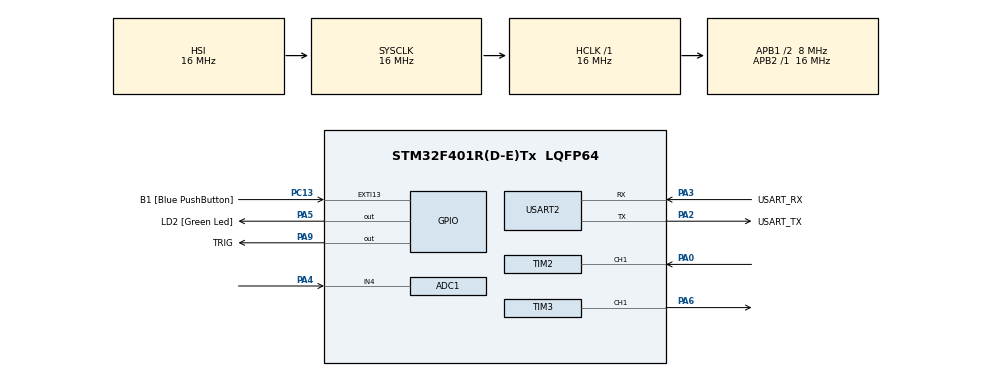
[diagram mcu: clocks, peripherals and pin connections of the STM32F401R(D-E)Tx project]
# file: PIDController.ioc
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ADC1.Channel-0\#ChannelRegularConversion=ADC_CHANNEL_4
ADC1.NbrOfConversionFlag=1
ADC1.Rank-0\#ChannelRegularConversion=1
ADC1.SamplingTime-0\#ChannelRegularConversion=ADC_SAMPLETIME_480CYCLES
ADC1.master=1
FREERTOS.Tasks01=defaultTask,24,128,StartDefaultTask,Default,NULL,Dynamic,NULL,NULL
FREERTOS.configTOTAL_HEAP_SIZE=24576
FREERTOS.configUSE_NEWLIB_REENTRANT=1
Mcu.Family=STM32F4
Mcu.Name=STM32F401R(D-E)Tx
Mcu.Package=LQFP64
NVIC.PriorityGroup=NVIC_PRIORITYGROUP_4
NVIC.TIM2_IRQn=true\:5\:0\:false\:false\:true\:true\:true\:true\:true
NVIC.TIM4_IRQn=true\:5\:0\:false\:false\:true\:true\:true\:true\:true
NVIC.TIM5_IRQn=true\:15\:0\:false\:false\:true\:false\:false\:true\:true
NVIC.TimeBase=TIM5_IRQn
NVIC.TimeBaseIP=TIM5
PA0-WKUP.Signal=S_TIM2_CH1_ETR
PA13.GPIO_Label=TMS
PA13.Mode=Serial_Wire
PA13.Signal=SYS_JTMS-SWDIO
PA14.GPIO_Label=TCK
PA14.Mode=Serial_Wire
PA14.Signal=SYS_JTCK-SWCLK
PA2.GPIO_Label=USART_TX
PA2.GPIO_Mode=GPIO_MODE_AF_PP
PA2.GPIO_PuPd=GPIO_NOPULL
PA2.GPIO_Speed=GPIO_SPEED_FREQ_LOW
PA2.Mode=Asynchronous
PA2.Signal=USART2_TX
PA3.GPIO_Label=USART_RX
PA3.GPIO_Mode=GPIO_MODE_AF_PP
PA3.GPIO_PuPd=GPIO_NOPULL
PA3.GPIO_Speed=GPIO_SPEED_FREQ_LOW
PA3.Mode=Asynchronous
PA3.Signal=USART2_RX
PA4.Signal=ADCx_IN4
PA5.GPIO_Label=LD2 [Green Led]
PA5.GPIO_Mode=GPIO_MODE_OUTPUT_PP
PA5.GPIO_PuPd=GPIO_NOPULL
PA5.GPIO_Speed=GPIO_SPEED_FREQ_LOW
PA5.Signal=GPIO_Output
PA6.Signal=S_TIM3_CH1
PA9.GPIO_Label=TRIG
PA9.Signal=GPIO_Output
PB3.GPIO_Label=SWO
PB3.Signal=SYS_JTDO-SWO
PC13-ANTI_TAMP.GPIO_Label=B1 [Blue PushButton]
PC13-ANTI_TAMP.GPIO_ModeDefaultEXTI=GPIO_MODE_IT_FALLING
PC13-ANTI_TAMP.GPIO_PuPd=GPIO_NOPULL
PC13-ANTI_TAMP.Signal=GPXTI13
PC14-OSC32_IN.Signal=RCC_OSC32_IN
PC15-OSC32_OUT.Signal=RCC_OSC32_OUT
PH0\ -\ OSC_IN.Signal=RCC_OSC_IN
PH1\ -\ OSC_OUT.Signal=RCC_OSC_OUT
ProjectManager.HeapSize=0x200
ProjectManager.StackSize=0x400
ProjectManager.TargetToolchain=STM32CubeIDE
RCC.48MHZClocksFreq_Value=18285714.285714287
RCC.AHBCLKDivider=RCC_SYSCLK_DIV1
RCC.AHBFreq_Value=16000000
RCC.APB1CLKDivider=RCC_HCLK_DIV2
RCC.APB1Freq_Value=8000000
RCC.APB1TimFreq_Value=16000000
RCC.APB2Freq_Value=16000000
RCC.APB2TimFreq_Value=16000000
RCC.CortexFreq_Value=16000000
RCC.HCLKFreq_Value=16000000
RCC.HSE_VALUE=8000000
RCC.HSI_VALUE=16000000
RCC.LSE_VALUE=32768
RCC.PLLM=8
RCC.PLLN=64
RCC.PLLQ=7
RCC.SYSCLKFreq_VALUE=16000000
RCC.SYSCLKSource=RCC_SYSCLKSOURCE_HSI
RCC.VCOOutputFreq_Value=128000000
SH.ADCx_IN4.0=ADC1_IN4,IN4
SH.S_TIM2_CH1_ETR.0=TIM2_CH1,Input_Capture1_from_TI1
SH.S_TIM3_CH1.0=TIM3_CH1,PWM Generation1 CH1
TIM2.Channel-Input_Capture1_from_TI1=TIM_CHANNEL_1
TIM2.Prescaler=15
TIM3.Channel-PWM\ Generation1\ CH1=TIM_CHANNEL_1
TIM3.Period=19999
TIM3.Prescaler=15
TIM3.Pulse-PWM\ Generation1\ CH1=1500
TIM4.Period=999
TIM4.Prescaler=1599
USART2.VirtualMode=VM_ASYNC
VP_FREERTOS_VS_CMSIS_V2.Mode=CMSIS_V2
VP_SYS_VS_tim5.Mode=TIM5
VP_TIM2_VS_ClockSourceINT.Mode=Internal
VP_TIM3_VS_ClockSourceINT.Mode=Internal
VP_TIM4_VS_ClockSourceINT.Mode=Internal
board=NUCLEO-F401RE

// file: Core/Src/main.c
/* USER CODE BEGIN Header */
/**
  ******************************************************************************
  * @file           : main.c
  * @brief          : Main program body
  ******************************************************************************
  * @attention
  *
  * Copyright (c) 2026 STMicroelectronics.
  * All rights reserved.
  *
  * This software is licensed under terms that can be found in the LICENSE file
  * in the root directory of this software component.
  * If no LICENSE file comes with this software, it is provided AS-IS.
  *
  ******************************************************************************
  */
/* USER CODE END Header */
#include "main.h"
#include "cmsis_os.h"
#include "adc.h"
#include "tim.h"
#include "usart.h"
#include "gpio.h"

/* USER CODE BEGIN Includes */
#include "app.h"        /* wiring de la aplicacion (todo lo nuestro vive en App/) */
/* USER CODE END Includes */

void SystemClock_Config(void);
void MX_FREERTOS_Init(void);

int main(void)
{

  /* MCU Configuration--------------------------------------------------------*/

  /* Reset of all peripherals, Initializes the Flash interface and the Systick. */
  HAL_Init();

  /* Configure the system clock */
  SystemClock_Config();

  /* Initialize all configured peripherals */
  MX_GPIO_Init();
  MX_TIM2_Init();
  MX_USART2_UART_Init();
  MX_TIM3_Init();
  MX_ADC1_Init();
  MX_TIM4_Init();
  /* USER CODE BEGIN 2 */
  App_Init();
  /* USER CODE END 2 */

  /* Init scheduler */

  /* Start scheduler */

  /* We should never get here as control is now taken by the scheduler */

  /* Infinite loop */
  /* USER CODE BEGIN WHILE */
  vTaskStartScheduler();
  while (1)
  {
    /* USER CODE END WHILE */

  }
}

void SystemClock_Config(void)
{
  RCC_OscInitTypeDef RCC_OscInitStruct = {0};
  RCC_ClkInitTypeDef RCC_ClkInitStruct = {0};

  /** Configure the main internal regulator output voltage
  */
  __HAL_RCC_PWR_CLK_ENABLE();
  __HAL_PWR_VOLTAGESCALING_CONFIG(PWR_REGULATOR_VOLTAGE_SCALE2);

  /** Initializes the RCC Oscillators according to the specified parameters
  * in the RCC_OscInitTypeDef structure.
  */
  RCC_OscInitStruct.OscillatorType = RCC_OSCILLATORTYPE_HSI;
  RCC_OscInitStruct.HSIState = RCC_HSI_ON;
  RCC_OscInitStruct.HSICalibrationValue = RCC_HSICALIBRATION_DEFAULT;
  RCC_OscInitStruct.PLL.PLLState = RCC_PLL_NONE;
  if (HAL_RCC_OscConfig(&RCC_OscInitStruct) != HAL_OK)
  {
    Error_Handler();
  }

  /** Initializes the CPU, AHB and APB buses clocks
  */
  RCC_ClkInitStruct.ClockType = RCC_CLOCKTYPE_HCLK|RCC_CLOCKTYPE_SYSCLK
                              |RCC_CLOCKTYPE_PCLK1|RCC_CLOCKTYPE_PCLK2;
  RCC_ClkInitStruct.SYSCLKSource = RCC_SYSCLKSOURCE_HSI;
  RCC_ClkInitStruct.AHBCLKDivider = RCC_SYSCLK_DIV1;
  RCC_ClkInitStruct.APB1CLKDivider = RCC_HCLK_DIV2;
  RCC_ClkInitStruct.APB2CLKDivider = RCC_HCLK_DIV1;

  if (HAL_RCC_ClockConfig(&RCC_ClkInitStruct, FLASH_LATENCY_0) != HAL_OK)
  {
    Error_Handler();
  }
}

/* USER CODE BEGIN 4 */

/* El HAL invoca este callback en cada captura de
 * Input Capture (contexto ISR). El dispatcher la entrega a la instancia del
 * sensor que corresponde. */
void HAL_TIM_IC_CaptureCallback(TIM_HandleTypeDef *htim)
{
  HC_SR04_HandleInterrupt(htim);
}

/* USER CODE END 4 */

void HAL_TIM_PeriodElapsedCallback(TIM_HandleTypeDef *htim)
{
  if (htim->Instance == TIM5)
  {
    HAL_IncTick();
  }
  /* USER CODE BEGIN Callback 1 */
  if (htim->Instance == TIM4)
  {
    App_OnTimerTick_FromISR();   /* tick de 100 ms -> despierta SensorTask */
  }
  /* USER CODE END Callback 1 */
}

void Error_Handler(void)
{
  __disable_irq();
  while (1)
  {
  }
}
